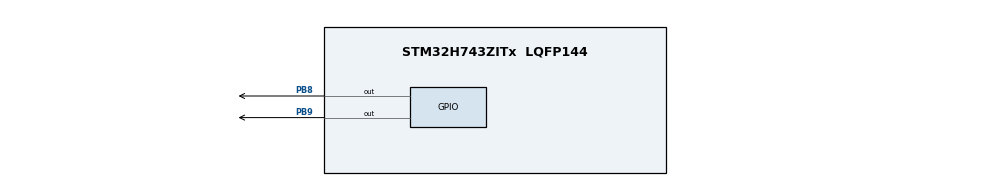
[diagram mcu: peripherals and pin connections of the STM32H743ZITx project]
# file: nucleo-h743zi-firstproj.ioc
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FREERTOS.Tasks01=Rng_sens,24,128,dist_measure,Default,NULL,Dynamic,NULL,NULL
Mcu.Family=STM32H7
Mcu.Name=STM32H743ZITx
Mcu.Package=LQFP144
NVIC.PriorityGroup=NVIC_PRIORITYGROUP_4
NVIC.TIM6_DAC_IRQn=true\:0\:0\:false\:false\:true\:false\:false\:true
NVIC.TimeBase=TIM6_DAC_IRQn
NVIC.TimeBaseIP=TIM6
PB8.Signal=GPIO_Output
PB9.Signal=GPIO_Output
ProjectManager.HeapSize=0x200
ProjectManager.StackSize=0x400
ProjectManager.TargetToolchain=STM32CubeIDE
RCC.ADCFreq_Value=129000000
RCC.APB1Freq_Value=64000000
RCC.APB2Freq_Value=64000000
RCC.APB3Freq_Value=64000000
RCC.APB4Freq_Value=64000000
RCC.CortexFreq_Value=64000000
RCC.HCLKFreq_Value=64000000
RCC.SYSCLKFreq_VALUE=64000000
RCC.USBFreq_Value=129000000
VP_FREERTOS_VS_CMSIS_V2.Mode=CMSIS_V2
VP_SYS_VS_tim6.Mode=TIM6
board=custom

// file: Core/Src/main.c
/* USER CODE BEGIN Header */
/**
  ******************************************************************************
  * @file           : main.c
  * @brief          : Main program body
  ******************************************************************************
  * @attention
  *
  * <h2><center>&copy; Copyright (c) 2020 STMicroelectronics.
  * All rights reserved.</center></h2>
  *
  * This software component is licensed by ST under BSD 3-Clause license,
  * the "License"; You may not use this file except in compliance with the
  * License. You may obtain a copy of the License at:
  *                        opensource.org/licenses/BSD-3-Clause
  *
  ******************************************************************************
  */
/* USER CODE END Header */
#include "main.h"
#include "cmsis_os.h"

/* Definitions for Rng_sens */
osThreadId_t Rng_sensHandle;
const osThreadAttr_t Rng_sens_attributes = {
  .name = "Rng_sens",
  .priority = (osPriority_t) osPriorityNormal,
  .stack_size = 128 * 4
};

void SystemClock_Config(void);
static void MX_GPIO_Init(void);
void dist_measure(void *argument);

int main(void)
{

  /* MCU Configuration--------------------------------------------------------*/

  /* Reset of all peripherals, Initializes the Flash interface and the Systick. */
  HAL_Init();

  /* Configure the system clock */
  SystemClock_Config();

  /* Initialize all configured peripherals */
  MX_GPIO_Init();

  /* Init scheduler */
  osKernelInitialize();

  /* Create the thread(s) */
  /* creation of Rng_sens */
  Rng_sensHandle = osThreadNew(dist_measure, NULL, &Rng_sens_attributes);

  /* Start scheduler */
  osKernelStart();

  /* We should never get here as control is now taken by the scheduler */
  /* Infinite loop */
  while (1)
  {

  }
}

void SystemClock_Config(void)
{
  RCC_OscInitTypeDef RCC_OscInitStruct = {0};
  RCC_ClkInitTypeDef RCC_ClkInitStruct = {0};

  /** Supply configuration update enable
  */
  HAL_PWREx_ConfigSupply(PWR_LDO_SUPPLY);
  /** Configure the main internal regulator output voltage
  */
  __HAL_PWR_VOLTAGESCALING_CONFIG(PWR_REGULATOR_VOLTAGE_SCALE3);

  while(!__HAL_PWR_GET_FLAG(PWR_FLAG_VOSRDY)) {}
  /** Initializes the RCC Oscillators according to the specified parameters
  * in the RCC_OscInitTypeDef structure.
  */
  RCC_OscInitStruct.OscillatorType = RCC_OSCILLATORTYPE_HSI;
  RCC_OscInitStruct.HSIState = RCC_HSI_DIV1;
  RCC_OscInitStruct.HSICalibrationValue = RCC_HSICALIBRATION_DEFAULT;
  RCC_OscInitStruct.PLL.PLLState = RCC_PLL_NONE;
  if (HAL_RCC_OscConfig(&RCC_OscInitStruct) != HAL_OK)
  {
    Error_Handler();
  }
  /** Initializes the CPU, AHB and APB buses clocks
  */
  RCC_ClkInitStruct.ClockType = RCC_CLOCKTYPE_HCLK|RCC_CLOCKTYPE_SYSCLK
                              |RCC_CLOCKTYPE_PCLK1|RCC_CLOCKTYPE_PCLK2
                              |RCC_CLOCKTYPE_D3PCLK1|RCC_CLOCKTYPE_D1PCLK1;
  RCC_ClkInitStruct.SYSCLKSource = RCC_SYSCLKSOURCE_HSI;
  RCC_ClkInitStruct.SYSCLKDivider = RCC_SYSCLK_DIV1;
  RCC_ClkInitStruct.AHBCLKDivider = RCC_HCLK_DIV1;
  RCC_ClkInitStruct.APB3CLKDivider = RCC_APB3_DIV1;
  RCC_ClkInitStruct.APB1CLKDivider = RCC_APB1_DIV1;
  RCC_ClkInitStruct.APB2CLKDivider = RCC_APB2_DIV1;
  RCC_ClkInitStruct.APB4CLKDivider = RCC_APB4_DIV1;

  if (HAL_RCC_ClockConfig(&RCC_ClkInitStruct, FLASH_LATENCY_0) != HAL_OK)
  {
    Error_Handler();
  }
}

static void MX_GPIO_Init(void)
{
  GPIO_InitTypeDef GPIO_InitStruct = {0};

  /* GPIO Ports Clock Enable */
  __HAL_RCC_GPIOB_CLK_ENABLE();

  /*Configure GPIO pin Output Level */
  HAL_GPIO_WritePin(GPIOB, GPIO_PIN_8|GPIO_PIN_9, GPIO_PIN_RESET);

  /*Configure GPIO pins : PB8 PB9 */
  GPIO_InitStruct.Pin = GPIO_PIN_8|GPIO_PIN_9;
  GPIO_InitStruct.Mode = GPIO_MODE_OUTPUT_PP;
  GPIO_InitStruct.Pull = GPIO_NOPULL;
  GPIO_InitStruct.Speed = GPIO_SPEED_FREQ_LOW;
  HAL_GPIO_Init(GPIOB, &GPIO_InitStruct);

}

void dist_measure(void *argument)
{
  /* USER CODE BEGIN 5 */
  /* Infinite loop */
  for(;;)
  {
    osDelay(1);
  }
  /* we should never get here.. but if we do, terminate the thread safely */
  osThreadTerminate(NULL);
  /* USER CODE END 5 */
}

void HAL_TIM_PeriodElapsedCallback(TIM_HandleTypeDef *htim)
{
  if (htim->Instance == TIM6) {
    HAL_IncTick();
  }
}

void Error_Handler(void)
{
}

/************************ (C) COPYRIGHT STMicroelectronics *****END OF FILE****/
